VERSION ""

NS_ :

BS_:

BU_: EAIT User

BO_ 409 LiDAR_aliv: 8 User
 SG_ LiDAR_alive_counter : 0|8@1+ (1,0) [0|255] ""  EAIT

BO_ 515 BSD_aliv: 8 User
 SG_ BSD_alive_counter : 0|8@1+ (1,0) [0|255] ""  EAIT

BO_ 516 TAKE_OVER_aliv: 8 User
 SG_ TAKE_OVER_alive_counter : 0|8@1+ (1,0) [0|255] ""  EAIT

BO_ 517 Lane_Keeping_aliv: 8 User
 SG_ Lane_Keeping_alive_counter : 0|8@1+ (1,0) [0|255] ""  EAIT

BO_ 518 Board_aliv: 8 User
 SG_ Board_alive_counter : 0|8@1+ (1,0) [0|255] ""  EAIT

BO_ 519 Safety_Warning_aliv: 8 User
 SG_ Safety_Warning_alive_counter : 0|8@1+ (1,0) [0|255] ""  EAIT

BO_ 520 Rtk_aliv: 8 User
 SG_ Rtk_alive_counter : 0|8@1+ (1,0) [0|255] ""  EAIT

BO_ 521 Local_Waypoint_aliv: 8 User
 SG_ Local_Waypoint_alive_counter : 0|8@1+ (1,0) [0|255] ""  EAIT

BO_ 529 AVM_aliv: 8 User
 SG_ AVM_alive_counter : 8|8@1+ (1,0) [0|255] ""  EAIT

BO_ 1814 INS_aliv: 8 User
 SG_ INS_alive_counter : 48|8@1+ (1,0) [0|255] ""  EAIT

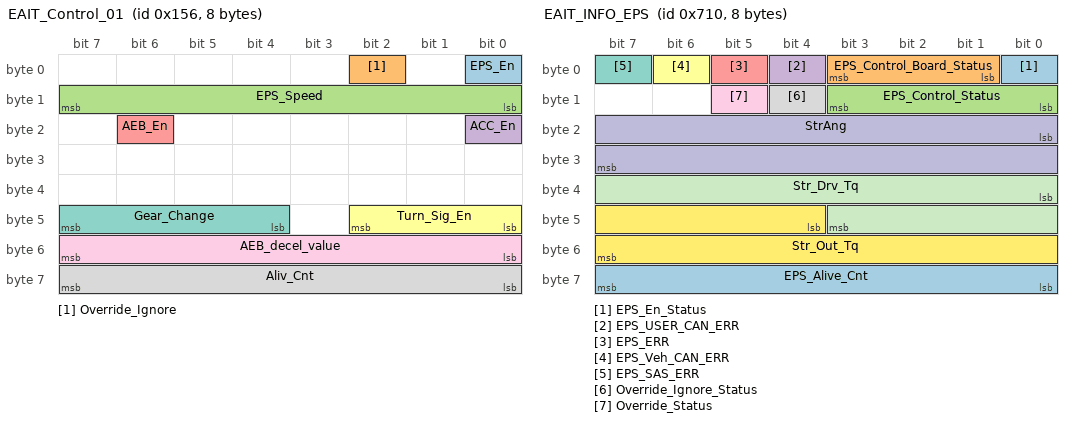
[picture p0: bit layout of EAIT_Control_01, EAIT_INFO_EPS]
BO_ 342 EAIT_Control_01: 8 User
 SG_ EPS_En : 0|1@1+ (1,0) [0|1] ""  EAIT
 SG_ Override_Ignore : 2|1@1+ (1,0) [0|1] ""  EAIT
 SG_ EPS_Speed : 8|8@1+ (1,0) [10|250] ""  EAIT
 SG_ ACC_En : 16|1@1+ (1,0) [0|0] ""  EAIT
 SG_ AEB_En : 22|1@1+ (1,0) [0|0] ""  EAIT
 SG_ Turn_Sig_En : 40|3@1+ (1,0) [0|4] ""  EAIT
 SG_ Gear_Change : 44|4@1+ (1,0) [0|8] ""  EAIT
 SG_ Aliv_Cnt : 56|8@1+ (1,0) [0|255] ""  EAIT
 SG_ AEB_decel_value : 48|8@1+ (0.01,0) [0|100] "g" Vector__XXX

BO_ 343 EAIT_Control_02: 8 User
 SG_ EPS_Cmd : 0|16@1- (0.1,0) [-500|500] "deg"  EAIT
 SG_ ACC_Cmd : 24|16@1+ (0.01,-10.23) [-4|2] "m/s"  EAIT

BO_ 1808 EAIT_INFO_EPS: 8 EAIT
 SG_ EPS_En_Status : 0|1@1+ (1,0) [0|1] ""  User
 SG_ EPS_Control_Board_Status : 1|3@1+ (1,0) [0|2] ""  User
 SG_ EPS_Control_Status : 8|4@1+ (1,0) [0|0] ""  User
 SG_ EPS_USER_CAN_ERR : 4|1@1+ (1,0) [0|0] ""  User
 SG_ EPS_ERR : 5|1@1+ (1,0) [0|0] ""  User
 SG_ EPS_Veh_CAN_ERR : 6|1@1+ (1,0) [0|0] ""  User
 SG_ EPS_SAS_ERR : 7|1@1+ (1,0) [0|0] ""  User
 SG_ Override_Ignore_Status : 12|1@1+ (1,0) [0|0] ""  User
 SG_ Override_Status : 13|1@1+ (1,0) [0|0] ""  User
 SG_ StrAng : 16|16@1- (0.1,0) [-500|500] ""  User
 SG_ Str_Drv_Tq : 32|12@1+ (0.01,-20.48) [-20.48|20.47] ""  User
 SG_ Str_Out_Tq : 44|12@1+ (0.1,-204.8) [-204.8|204.7] ""  User
 SG_ EPS_Alive_Cnt : 56|8@1+ (1,0) [0|255] ""  User

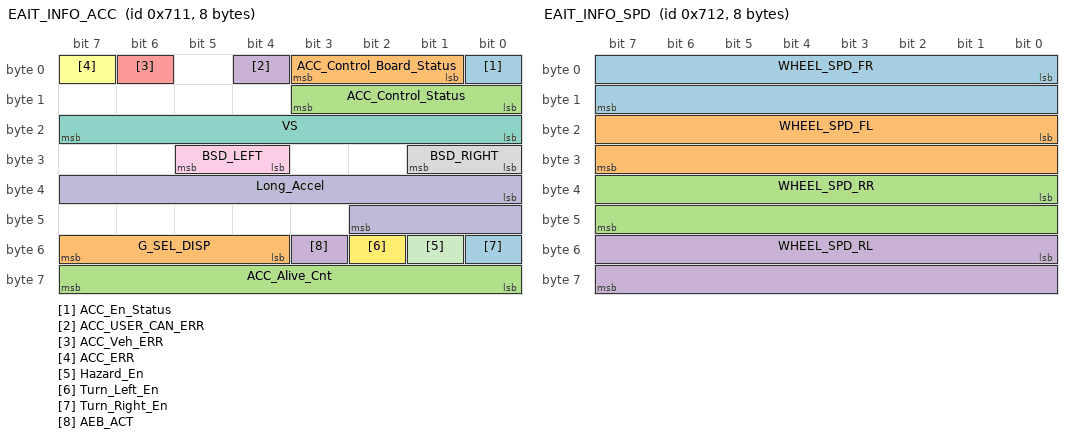
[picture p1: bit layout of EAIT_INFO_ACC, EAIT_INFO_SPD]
BO_ 1809 EAIT_INFO_ACC: 8 EAIT
 SG_ ACC_En_Status : 0|1@1+ (1,0) [0|0] ""  User
 SG_ ACC_Control_Board_Status : 1|3@1+ (1,0) [0|0] ""  User
 SG_ ACC_Control_Status : 8|4@1+ (1,0) [0|0] ""  User
 SG_ ACC_USER_CAN_ERR : 4|1@1+ (1,0) [0|0] ""  User
 SG_ ACC_Veh_ERR : 6|1@1+ (1,0) [0|0] ""  User
 SG_ ACC_ERR : 7|1@1+ (1,0) [0|0] ""  User
 SG_ VS : 16|8@1+ (1,0) [0|255] "km/h"  User
 SG_ BSD_RIGHT : 24|2@1+ (1,0) [0|0] ""  User
 SG_ BSD_LEFT : 28|2@1+ (1,0) [0|0] ""  User
 SG_ Long_Accel : 32|11@1+ (0.01,-10.23) [0|0] "m/s^2"  User
 SG_ Hazard_En : 49|1@1+ (1,0) [0|0] ""  User
 SG_ Turn_Left_En : 50|1@1+ (1,0) [0|0] ""  User
 SG_ Turn_Right_En : 48|1@1+ (1,0) [0|0] ""  User
 SG_ G_SEL_DISP : 52|4@1+ (1,0) [0|0] ""  User
 SG_ ACC_Alive_Cnt : 56|8@1+ (1,0) [0|255] ""  User
 SG_ AEB_ACT : 51|1@1+ (1,0) [0|0] "" Vector__XXX

BO_ 1810 EAIT_INFO_SPD: 8 EAIT
 SG_ WHEEL_SPD_FR : 0|16@1+ (0.03125,0) [0|511.96875] ""  User
 SG_ WHEEL_SPD_FL : 16|16@1+ (0.03125,0) [0|511.96875] ""  User
 SG_ WHEEL_SPD_RR : 32|16@1+ (0.03125,0) [0|511.96875] ""  User
 SG_ WHEEL_SPD_RL : 48|16@1+ (0.03125,0) [0|511.96875] ""  User

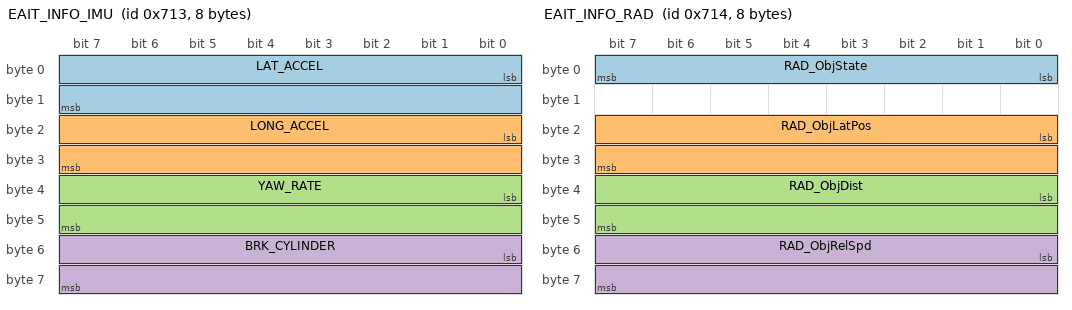
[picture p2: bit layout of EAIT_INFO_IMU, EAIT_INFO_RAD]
BO_ 1811 EAIT_INFO_IMU: 8 EAIT
 SG_ LAT_ACCEL : 0|16@1- (0.01,-10.23) [-10.23|10.23] "m/s^2"  User
 SG_ LONG_ACCEL : 16|16@1- (0.01,-10.23) [-10.23|10.23] "m/s^2"  User
 SG_ YAW_RATE : 32|16@1- (0.01,-40.95) [-40.95|40.94] "deg/s"  User
 SG_ BRK_CYLINDER : 48|16@1+ (0.1,0) [0|409.4] ""  User

BO_ 1812 EAIT_INFO_RAD: 8 EAIT
 SG_ RAD_ObjState : 0|8@1+ (1,0) [0|4] ""  User
 SG_ RAD_ObjLatPos : 16|16@1+ (0.1,-20) [-20|31.1] "m"  User
 SG_ RAD_ObjDist : 32|16@1+ (0.1,0) [0|204.7] "m"  User
 SG_ RAD_ObjRelSpd : 48|16@1+ (0.1,-170) [-170|239.5] "m/s"  User

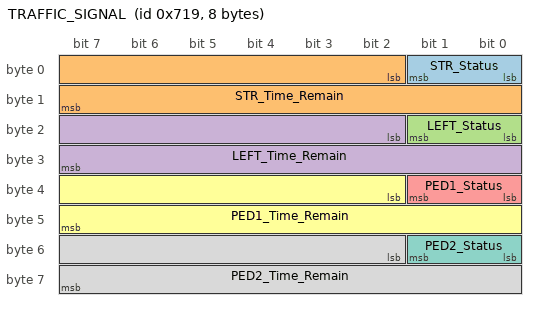
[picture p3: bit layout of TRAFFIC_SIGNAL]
BO_ 1817 TRAFFIC_SIGNAL: 8 EAIT
 SG_ STR_Status : 0|2@1+ (1,0) [0|4] ""  User
 SG_ STR_Time_Remain : 2|14@1+ (0.1,0) [0|1000] ""  User
 SG_ LEFT_Status : 16|2@1+ (1,0) [0|4] ""  User
 SG_ LEFT_Time_Remain : 18|14@1+ (0.1,0) [0|1000] ""  User
 SG_ PED1_Status : 32|2@1+ (1,0) [0|4] ""  User
 SG_ PED1_Time_Remain : 34|14@1+ (0.1,0) [0|1000] ""  User
 SG_ PED2_Status : 48|2@1+ (1,0) [0|4] ""  User
 SG_ PED2_Time_Remain : 50|14@1+ (0.1,0) [0|1000] ""  User

CM_ SG_ 342 EPS_Speed "Default 150";
CM_ SG_ 1808 EPS_Control_Status "Other value : error";
CM_ SG_ 1808 EPS_USER_CAN_ERR "User_CAN_Error. if this signal is activate, AEB operate.";
CM_ SG_ 1808 EPS_SAS_ERR "Steering angle sensor error";
CM_ SG_ 1808 Override_Status "If override occur, values is 1 during 1 second";
CM_ SG_ 1809 ACC_Control_Status "Other value : error";
CM_ SG_ 1809 BSD_RIGHT "Option";
CM_ SG_ 1809 BSD_LEFT "Option
";
CM_ BO_ 1812 "Option";
BA_DEF_  "BusType" STRING ;
BA_DEF_DEF_  "BusType" "CAN";
VAL_ 342 EPS_En 0 "EPS_Off" 1 "EPS_On" ;
VAL_ 342 Override_Ignore 0 "Do_Override" 1 "Do_Ignore" ;
VAL_ 342 ACC_En 0 "ACC_Off" 1 "ACC_On" ;
VAL_ 342 AEB_En 0 "AEB_Off" 1 "AEB_On" ;
VAL_ 342 Turn_Sig_En 0 "Off" 1 "Hazard" 2 "Left" 4 "Right" ;
VAL_ 342 Gear_Change 8 "P" 4 "R" 2 "N" 1 "D" ;
VAL_ 1808 EPS_En_Status 0 "EPS_Off" 1 "EPS_On" ;
VAL_ 1808 EPS_Control_Board_Status 0 "Abnormal" 1 "Initial" 2 "Normal" ;
VAL_ 1808 EPS_Control_Status 0 "None" 1 "Ready" 2 "All_On" 3 "ACC_On" 4 "EPS_On" ;
VAL_ 1808 EPS_USER_CAN_ERR 0 "Normal" 1 "Abnormal" ;
VAL_ 1808 EPS_ERR 0 "Normal" 1 "Abnormal" ;
VAL_ 1808 EPS_Veh_CAN_ERR 0 "Normal" 1 "Abnormal" ;
VAL_ 1808 EPS_SAS_ERR 0 "Normal" 1 "Abnormal" ;
VAL_ 1808 Override_Ignore_Status 0 "Do_Override" 1 "Do_Ignore" ;
VAL_ 1808 Override_Status 0 "Normal" 1 "Override" ;
VAL_ 1809 ACC_En_Status 0 "ACC_Off" 1 "ACC_On" ;
VAL_ 1809 ACC_Control_Board_Status 0 "Abnormal" 1 "Initial" 2 "Normal" ;
VAL_ 1809 ACC_Control_Status 0 "None" 1 "Ready" 2 "All_On" 3 "ACC_On" 4 "EPS_On" ;
VAL_ 1809 ACC_USER_CAN_ERR 0 "Normal" 1 "Abnormal" ;
VAL_ 1809 ACC_Veh_ERR 0 "Normal" 1 "Abnormal" ;
VAL_ 1809 ACC_ERR 0 "Normal" 1 "Abnormal" ;
VAL_ 1809 Hazard_En 0 "Off" 1 "On" ;
VAL_ 1809 Turn_Left_En 0 "Off" 1 "On" ;
VAL_ 1809 Turn_Right_En 0 "Off" 1 "On" ;
VAL_ 1809 G_SEL_DISP 0 "P" 7 "R" 6 "N" 5 "D" ;
